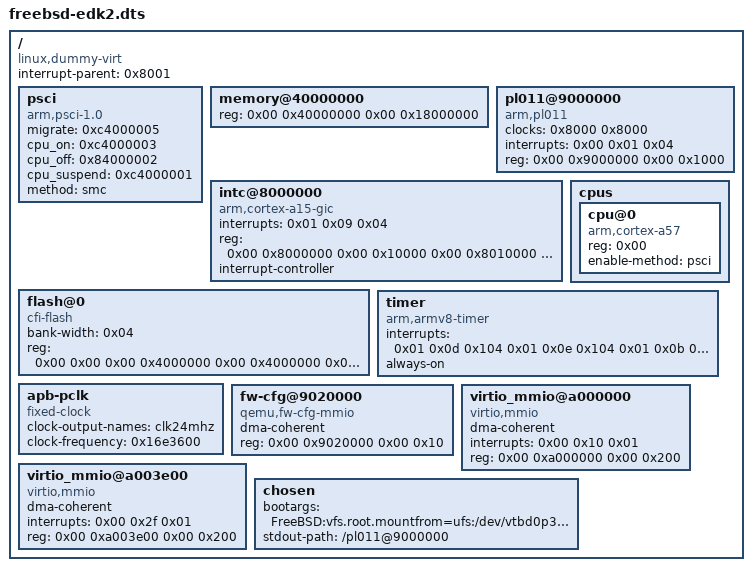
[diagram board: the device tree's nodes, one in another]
/dts-v1/;

/*
 * freebsd-edk2.dts — Direct FreeBSD kernel FDT for QEMU virt/aarch64.
 *
 * Memory layout (must match freebsd_vmm_test.system guest_ram):
 *   384 MB (0x18000000) at guest phys 0x40000000
 *
 * PSCI: SMC method — seL4 intercepts HVC from VCPU EL1 as a seL4 syscall,
 * not a VCPUFault, so we use SMC.  libvmm fault.c routes SMC to handle_psci().
 *
 * Boot arguments must start with "FreeBSD:"; the arm64 kernel intentionally
 * ignores generic Linux-style bootargs without that prefix.
 */

/ {
	interrupt-parent = <0x8001>;
	#size-cells = <0x02>;
	#address-cells = <0x02>;
	compatible = "linux,dummy-virt";

	psci {
		migrate = <0xc4000005>;
		cpu_on = <0xc4000003>;
		cpu_off = <0x84000002>;
		cpu_suspend = <0xc4000001>;
		method = "smc";
		compatible = "arm,psci-1.0\0arm,psci-0.2\0arm,psci";
	};

	/* 384 MB — matches guest_ram MR size in freebsd_vmm_test.system */
	memory@40000000 {
		reg = <0x00 0x40000000 0x00 0x18000000>;
		device_type = "memory";
	};

	pl011@9000000 {
		clock-names = "uartclk\0apb_pclk";
		clocks = <0x8000 0x8000>;
		interrupts = <0x00 0x01 0x04>;
		reg = <0x00 0x9000000 0x00 0x1000>;
		compatible = "arm,pl011\0arm,primecell";
	};

	/* GIC: distributor + CPU interface + hypervisor + virtual CPU interface */
	intc@8000000 {
		phandle = <0x8001>;
		interrupts = <0x01 0x09 0x04>;
		reg = <0x00 0x8000000 0x00 0x10000
		       0x00 0x8010000 0x00 0x10000
		       0x00 0x8030000 0x00 0x10000
		       0x00 0x8040000 0x00 0x10000>;
		compatible = "arm,cortex-a15-gic";
		ranges;
		#size-cells = <0x02>;
		#address-cells = <0x02>;
		interrupt-controller;
		#interrupt-cells = <0x03>;
	};

	/* EDK2 code flash + UEFI variable store */
	flash@0 {
		bank-width = <0x04>;
		reg = <0x00 0x00 0x00 0x4000000
		       0x00 0x4000000 0x00 0x4000000>;
		compatible = "cfi-flash";
	};

	cpus {
		#size-cells = <0x00>;
		#address-cells = <0x01>;

		cpu@0 {
			reg = <0x00>;
			enable-method = "psci";
			compatible = "arm,cortex-a57";
			device_type = "cpu";
		};
	};

	timer {
		interrupts = <0x01 0x0d 0x104
		              0x01 0x0e 0x104
		              0x01 0x0b 0x104
		              0x01 0x0a 0x104>;
		always-on;
		compatible = "arm,armv8-timer\0arm,armv7-timer";
	};

	apb-pclk {
		phandle = <0x8000>;
		clock-output-names = "clk24mhz";
		clock-frequency = <0x16e3600>;
		#clock-cells = <0x00>;
		compatible = "fixed-clock";
	};

	/*
	 * QEMU fw_cfg MMIO without the optional DMA aperture.
	 *
	 * EDK2 enables fw_cfg DMA when the node exposes the 0x10..0x17 DMA
	 * address register.  That is unsafe in agentOS: the FreeBSD guest IPA is
	 * mapped through seL4 page tables, so a guest DMA address is not
	 * necessarily the same as the outer QEMU machine physical address.  Keep
	 * fw_cfg in register I/O mode; the virtio-mmio nodes below give EDK2 the
	 * block and network devices it needs without ACPI-table DMA.
	 */
	fw-cfg@9020000 {
		dma-coherent;
		reg = <0x00 0x9020000 0x00 0x10>;
		compatible = "qemu,fw-cfg-mmio";
	};

	/* virtio-net-device on QEMU virt bus 0: PA 0xa000000, SPI 16 = INTID 48. */
	virtio_mmio@a000000 {
		dma-coherent;
		interrupts = <0x00 0x10 0x01>;
		reg = <0x00 0xa000000 0x00 0x200>;
		compatible = "virtio,mmio";
	};

	/*
	 * VirtIO-MMIO: only slot 31 (the actual virtio-blk-device).
	 * QEMU assigns -device virtio-blk-device to bus 31 (highest available),
	 * at 0xa003e00, SPI 47 = INTID 79, edge trigger.
	 *
	 * Only the occupied slot is listed, matching QEMU's auto-generated FDT
	 * which omits empty slots.  VirtioFdtDxe creates one handle here;
	 * VirtioBlkDxe connects to it.  The full virtio_mmio MR (0xa000000,
	 * size 0x4000) is still mapped in the .system file.
	 *
	 * dma-coherent is required — without it VirtioMmioInstallDevice requires
	 * gEdkiiIoMmuProtocolGuid (not available) and returns EFI_UNSUPPORTED.
	 */
	virtio_mmio@a003e00 {
		dma-coherent;
		interrupts = <0x00 0x2f 0x01>;
		reg = <0x00 0xa003e00 0x00 0x200>;
		compatible = "virtio,mmio";
	};

	chosen {
		bootargs = "FreeBSD:vfs.root.mountfrom=ufs:/dev/vtbd0p3 console=ttyu0";
		stdout-path = "/pl011@9000000";
	};
};
